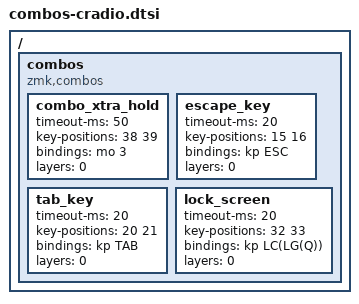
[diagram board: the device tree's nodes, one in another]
/ {
    combos {
        compatible = "zmk,combos";

        // Ported from /Users/tjennerjahn/Documents/Keyboards/zmk-config/config/cradio.keymap

        // Momentary Xtra layer while holding the inner thumbs (one per half).
        combo_xtra_hold {
            timeout-ms = <50>;
            key-positions = <38 39>;
            bindings = <&mo 3>;
            layers = <0>;
        };

        // ESC when D+F are tapped (base layer only).
        escape_key {
            timeout-ms = <20>;
            key-positions = <15 16>;
            bindings = <&kp ESC>;
            layers = <0>;
        };

        // TAB when K+L are tapped (base layer only).
        tab_key {
            timeout-ms = <20>;
            key-positions = <20 21>;
            bindings = <&kp TAB>;
            layers = <0>;
        };

        // macOS lock screen (Ctrl+Cmd+Q) when ,+. are tapped (base layer only).
        lock_screen {
            timeout-ms = <20>;
            key-positions = <32 33>;
            bindings = <&kp LC(LG(Q))>;
            layers = <0>;
        };

        // Bootloader is directly bound on the Xtra layer (see layer_3 in qwerty.keymap).
    };
};
